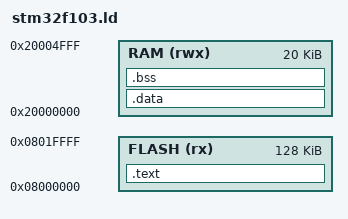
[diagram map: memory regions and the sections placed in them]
MEMORY
{
    FLASH (rx)  : ORIGIN = 0x08000000, LENGTH = 128K
    RAM   (rwx) : ORIGIN = 0x20000000, LENGTH = 20K
}

SECTIONS
{
    .text :
    {
        . = ALIGN(4);
        KEEP(*(.isr_vector))
        *(.text)
        *(.text*)
        *(.rodata)
        *(.rodata*)
        . = ALIGN(4);
        _etext = .;
    } > FLASH

    .data : AT (_etext)
    {
        . = ALIGN(4);
        _sdata = .;
        *(.data)
        *(.data*)
        . = ALIGN(4);
        _edata = .;
    } > RAM

    _sidata = LOADADDR(.data);

    .bss :
    {
        . = ALIGN(4);
        _sbss = .;
        *(.bss)
        *(.bss*)
        *(COMMON)
        . = ALIGN(4);
        _ebss = .;
    } > RAM

    _estack = ORIGIN(RAM) + LENGTH(RAM);
}
